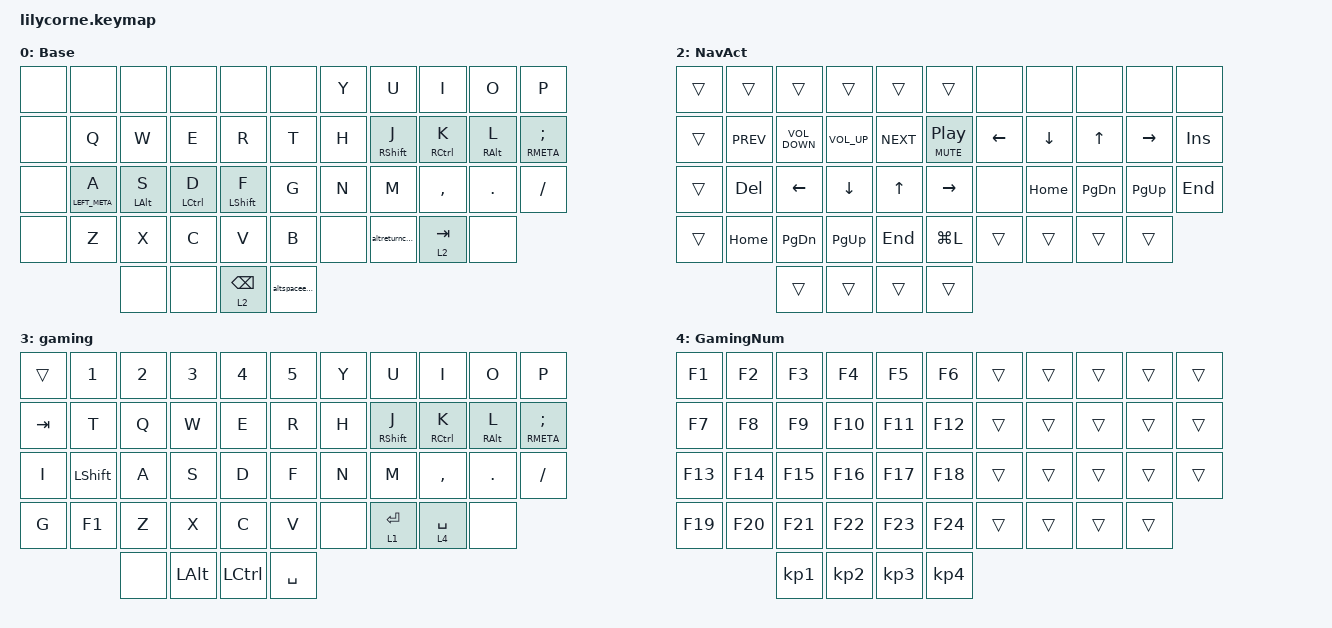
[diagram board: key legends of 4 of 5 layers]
#include <behaviors.dtsi>
#include <dt-bindings/zmk/keys.h>
#include <dt-bindings/zmk/bt.h>

#define BT_SSP_DISABLE 1

/ {
    behaviors {
        hm: homerow_mods {
            compatible = "zmk,behavior-hold-tap";
            label = "HOMEROW_MODS";
            bindings = <&kp>, <&kp>;

            #binding-cells = <2>;
            tapping-term-ms = <200>;
            flavor = "tap-preferred";
            require-prior-idle-ms = <125>;
            quick-tap-ms = <200>;
        };

        shifthr: shifthr {
            compatible = "zmk,behavior-hold-tap";
            label = "SHIFTHR";
            bindings = <&kp>, <&kp>;

            #binding-cells = <2>;
            tapping-term-ms = <185>;
            flavor = "tap-preferred";
            quick-tap-ms = <185>;
        };

        weak: weak {
            compatible = "zmk,behavior-hold-tap";
            label = "WEAK";
            bindings = <&kp>, <&kp>;

            #binding-cells = <2>;
            tapping-term-ms = <230>;
            flavor = "tap-preferred";
            require-prior-idle-ms = <125>;
            quick-tap-ms = <230>;
        };

        backspace: backspace {
            compatible = "zmk,behavior-tap-dance";
            label = "BACKSPACE";
            #binding-cells = <0>;
            bindings = <&kp BACKSPACE>, <&kp LC(BACKSPACE)>;
        };

        altspaceescape: altspaceescape {
            compatible = "zmk,behavior-mod-morph";
            label = "ALTSPACEESCAPE";
            bindings = <&lt 1 SPACE>, <&kp ESCAPE>;

            #binding-cells = <0>;
            mods = <(MOD_LALT)>;
        };

        altreturncaps: altreturncaps {
            compatible = "zmk,behavior-mod-morph";
            label = "ALTRETURNCAPS";
            bindings = <&lt 1 RET>, <&kp CAPS>;

            #binding-cells = <0>;
            mods = <(MOD_RALT)>;
        };

        bluetoothSelORClear: bluetoothSelORClear {
            compatible = "zmk,behavior-hold-tap";
            label = "BLUETOOTHSELORCLEAR";
            bindings = <&bt>, <&bt>;

            #binding-cells = <2>;
            tapping-term-ms = <20>;
        };
    };

    combos {
        compatible = "zmk,combos";

        togglegamelayer {
            bindings = <&tog 4>;
            key-positions = <38 37>;
        };

        game-escape {
            bindings = <&kp ESCAPE>;
            key-positions = <2 1>;
            layers = <4 3>;
        };

        gaming-enter {
            bindings = <&kp ENTER>;
            key-positions = <4 3>;
            layers = <4 3>;
        };
    };

    keymap {
        compatible = "zmk,keymap";

        base {
            display-name = "Base";
            bindings = <
&none  &none              &none             &none                    &none                  &none                                &kp Y           &kp U             &kp I             &kp O              &kp P             
&none  &kp Q              &kp W             &kp E                    &kp R                  &kp T                                &kp H           &shifthr RSHFT J  &shifthr RCTRL K  &weak RIGHT_ALT L  &weak RMETA SEMI 
&none  &weak LEFT_META A  &weak LEFT_ALT S  &shifthr LEFT_CONTROL D  &shifthr LEFT_SHIFT F  &kp G                                &kp N           &kp M             &kp COMMA         &kp PERIOD         &kp FSLH        
&none  &kp Z              &kp X             &kp C                    &kp V                  &kp B              &none             &altreturncaps  &lt 2 TAB         &none
                          &none             &none                    &lt 2 BACKSPACE        &altspaceescape    			  		
            >;
        };

        NumSym {
            display-name = "NumSym";
            bindings = <
&trans  &trans              &trans                          &trans                      &trans                                  &trans                      &mt F16 F6       &mt F17 F7       &mt F18 F8         &mt F19 F9            &mt F20 F10                 
&none   &mt F11 F1          &mt F12 F2                      &mt F13 F3                  &mt F14 F4                              &mt F15 F5                  &mt CARET N6     &mt AMPS N7      &mt ASTERISK N8    &mt F19 F9            &mt DOUBLE_QUOTES N0 
&none   &mt EXCLAMATION N1  &mt AT N2                       &mt POUND N3                &mt DOLLAR N4                           &mt PERCENT N5              &none   	     &mt CARET TILDE  &mt UNDER KP_SUBTRACT  &mt EQUAL KP_PLUS  &mt NON_US_HASH APOS  &mt GRAVE PIPE
&none   &none               &mt RIGHT_BRACKET LEFT_BRACKET  &mt RIGHT_BRACE LEFT_BRACE  &mt RIGHT_PARENTHESIS LEFT_PARENTHESIS  &none           &none       &trans           &trans           &trans
                            &trans			    &trans     	 	        &trans				        &trans          	     
            >;
        };

        NavAct {
            bindings = <
&trans  &trans      &trans             &trans           &trans      &trans                                &none     &none     &none          &none         &none      
&trans  &kp C_PREV  &kp C_VOLUME_DOWN  &kp C_VOLUME_UP  &kp C_NEXT  &mt C_MUTE C_PLAY_PAUSE               &kp LEFT  &kp DOWN  &kp UP_ARROW   &kp RIGHT     &kp INS 
&trans  &kp DELETE  &kp LEFT           &kp DOWN         &kp UP_ARROW &kp RIGHT                            &none     &kp HOME  &kp PAGE_DOWN  &kp PAGE_UP   &kp END    
&trans  &kp HOME    &kp PAGE_DOWN      &kp PAGE_UP      &kp END     &kp LG(L)   &trans           	  &trans    &trans    &trans   
                    &trans             &trans           &trans      &trans                       
            >;
        };

        gaming {
            display-name = "gaming";
            bindings = <
&trans   &kp NUMBER_1    &kp NUMBER_2  &kp NUMBER_3  &kp NUMBER_4  &kp N5                                    &kp Y       &kp U             &kp I             &kp O              &kp P             
&kp TAB  &kp T           &kp Q         &kp W         &kp E         &kp R                                     &kp H       &shifthr RSHFT J  &shifthr RCTRL K  &weak RIGHT_ALT L  &weak RMETA SEMI 
&kp I    &kp LEFT_SHIFT  &kp A         &kp S         &kp D         &kp F                                     &kp N       &kp M             &kp COMMA         &kp DOT            &kp FSLH       
&kp G    &kp F1          &kp Z         &kp X         &kp C         &kp V  &none		                     &lt 1 RET   &lt 4 SPACE  	   &none
                         &none         &kp LEFT_ALT  &kp LEFT_CONTROL  &kp SPACE    			                  
            >;
        };

        GamingNum {
            bindings = <
&kp F1   &kp F2   &kp F3   &kp F4     &kp F5     &kp F6                          &trans  &trans  &trans  &trans  &trans
&kp F7   &kp F8   &kp F9   &kp F10    &kp F11    &kp F12                         &trans  &trans  &trans  &trans  &trans
&kp F13  &kp F14  &kp F15  &kp F16    &kp F17    &kp F18                         &trans  &trans  &trans  &trans  &trans
&kp F19  &kp F20  &kp F21  &kp F22    &kp F23    &kp F24    &trans               &trans  &trans  &trans
                  &kp KP_N1  &kp KP_N2  &kp KP_N3  &kp KP_N4                     
            >;
        };
    };
};


